VERSION ""

NS_ :

BS_:

BU_:

VAL_TABLE_ OnOff 1 "on" 0 "off" ;

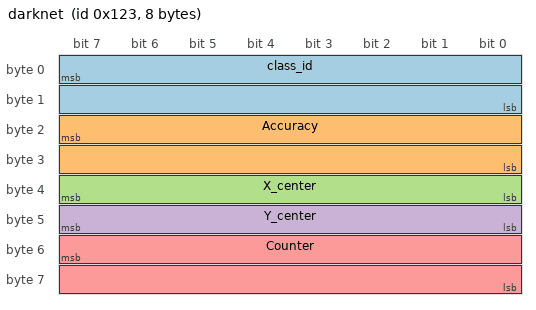
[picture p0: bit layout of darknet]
BO_ 291 darknet: 8 Vector__XXX
 SG_ class_id : 7|16@0+ (1,0) [0|0] "" Vector__XXX
 SG_ Accuracy : 23|16@0+ (0.01,0) [0|0] "" Vector__XXX
 SG_ X_center : 39|8@0+ (0.01,0) [0|0] "" Vector__XXX
 SG_ Y_center : 47|8@0+ (0.01,0) [0|0] "" Vector__XXX
 SG_ Counter : 55|16@0+ (0.01,0) [0|0] "" Vector__XXX
